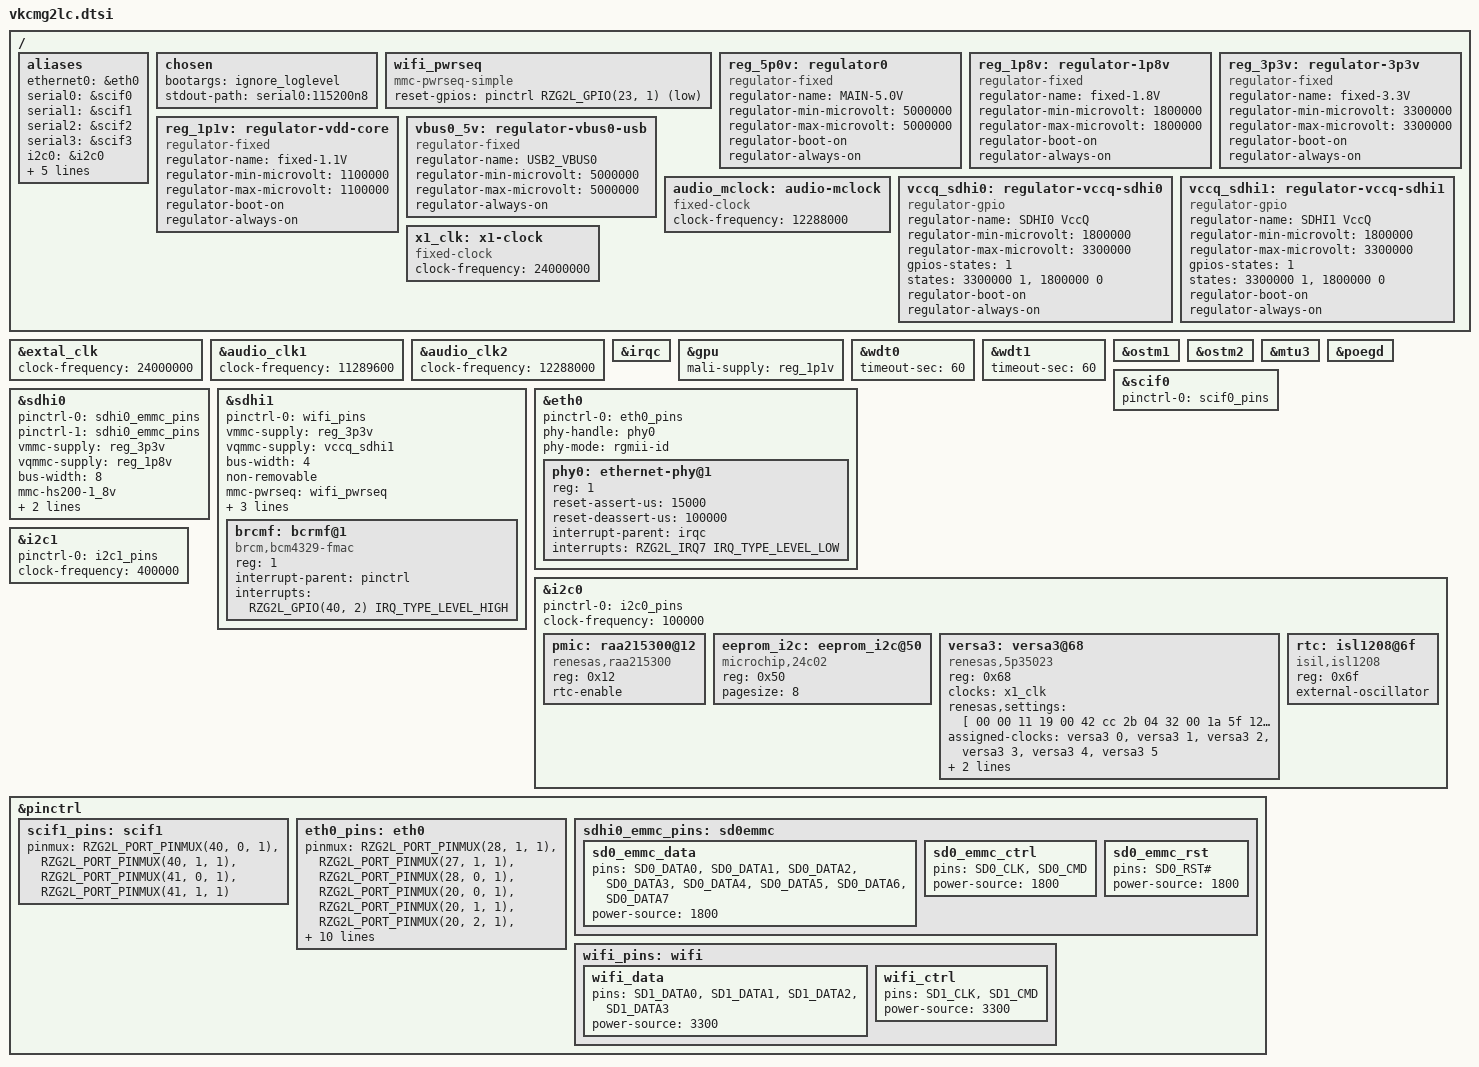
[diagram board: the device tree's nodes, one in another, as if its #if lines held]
// SPDX-License-Identifier: GPL-2.0
/*
 * Device Tree Source for the Vekatech (VKRZG2LC Dual Cortex-A55)
 *
 * Copyright (C) 2026 Vekatech.
 */

#include <dt-bindings/gpio/gpio.h>
#include <dt-bindings/interrupt-controller/irqc-rzg2l.h>
#include <dt-bindings/pinctrl/rzg2l-pinctrl.h>
#include <dt-bindings/input/input.h>


/ {
	aliases {
		ethernet0 = &eth0;
		serial0 = &scif0;
		serial1 = &scif1;
		serial2 = &scif2;
		serial3 = &scif3;
		i2c0 = &i2c0;
		i2c1 = &i2c1;
		i2c2 = &i2c2;
		i2c3 = &i2c3;
		mmc0 = &sdhi0;
		mmc1 = &sdhi1;
	};

	chosen {
		bootargs = "ignore_loglevel";
		stdout-path = "serial0:115200n8";
	};

#if WIFI_MODULE_1YN
	wifi_pwrseq: wifi_pwrseq {
		compatible = "mmc-pwrseq-simple";
		reset-gpios = <&pinctrl RZG2L_GPIO(23, 1) GPIO_ACTIVE_LOW>;
	};
#endif
	reg_5p0v: regulator0 {
		compatible = "regulator-fixed";
		regulator-name = "MAIN-5.0V";
		regulator-min-microvolt = <5000000>;
		regulator-max-microvolt = <5000000>;
		regulator-boot-on;
		regulator-always-on;
	};

	reg_1p8v: regulator-1p8v {
		compatible = "regulator-fixed";
		regulator-name = "fixed-1.8V";
		regulator-min-microvolt = <1800000>;
		regulator-max-microvolt = <1800000>;
		regulator-boot-on;
		regulator-always-on;
	};

	reg_3p3v: regulator-3p3v {
		compatible = "regulator-fixed";
		regulator-name = "fixed-3.3V";
		regulator-min-microvolt = <3300000>;
		regulator-max-microvolt = <3300000>;
		regulator-boot-on;
		regulator-always-on;
	};

	reg_1p1v: regulator-vdd-core {
		compatible = "regulator-fixed";
		regulator-name = "fixed-1.1V";
		regulator-min-microvolt = <1100000>;
		regulator-max-microvolt = <1100000>;
		regulator-boot-on;
		regulator-always-on;
	};

	vbus0_5v: regulator-vbus0-usb {
		compatible = "regulator-fixed";
		regulator-name = "USB2_VBUS0";
		regulator-min-microvolt = <5000000>;
		regulator-max-microvolt = <5000000>;
		regulator-always-on;
	};

	audio_mclock: audio-mclock {
		compatible = "fixed-clock";
		#clock-cells = <0>;
		clock-frequency = <12288000>;
	};

	vccq_sdhi0: regulator-vccq-sdhi0 {
		compatible = "regulator-gpio";
		regulator-name = "SDHI0 VccQ";
		regulator-min-microvolt = <1800000>;
		regulator-max-microvolt = <3300000>;
		gpios-states = <1>;
		states = <3300000 1>, <1800000 0>;
		regulator-boot-on;
		regulator-always-on;
	};

	vccq_sdhi1: regulator-vccq-sdhi1 {
		compatible = "regulator-gpio";
		regulator-name = "SDHI1 VccQ";
		regulator-min-microvolt = <1800000>;
		regulator-max-microvolt = <3300000>;
		gpios-states = <1>;
		states = <3300000 1>, <1800000 0>;
		regulator-boot-on;
		regulator-always-on;
	};

	x1_clk: x1-clock {
		compatible = "fixed-clock";
		#clock-cells = <0>;
		clock-frequency = <24000000>;
	};
};

&extal_clk {
	clock-frequency = <24000000>;
};

&audio_clk1{
	clock-frequency = <11289600>;
};

&audio_clk2{
	clock-frequency = <12288000>;
};

&irqc {
	status = "okay";
};

&gpu {
	mali-supply = <&reg_1p1v>;
};

&wdt0 {
	status = "okay";
	timeout-sec = <60>;
};

&wdt1 {
	status = "okay";
	timeout-sec = <60>;
};

&ostm1 {
	status = "okay";
};

&ostm2 {
	status = "okay";
};

&mtu3 {
	status = "okay";
};

&poegd {
	status = "okay";
};

&scif0 {
	pinctrl-0 = <&scif0_pins>;
	pinctrl-names = "default";
	status = "okay";
};

/* for eMMC */
&sdhi0 {
	pinctrl-0 = <&sdhi0_emmc_pins>;
	pinctrl-1 = <&sdhi0_emmc_pins>;
	pinctrl-names = "default", "state_uhs";

	vmmc-supply = <&reg_3p3v>;
	vqmmc-supply = <&reg_1p8v>;
	bus-width = <8>;
	mmc-hs200-1_8v;
	non-removable;
	fixed-emmc-driver-type = <1>;
	status = "okay";
};

#if WIFI_MODULE_1YN

/* Wifi */
&sdhi1 {
	status = "okay";

	#address-cells = <1>;
	#size-cells = <0>;

	pinctrl-names = "default";
	pinctrl-0 = <&wifi_pins>;
	vmmc-supply = <&reg_3p3v>;
	vqmmc-supply = <&vccq_sdhi1>;
	bus-width = <4>;
	non-removable;
	mmc-pwrseq = <&wifi_pwrseq>;
        cap-sd-highspeed;
	cap-power-off-card;
	keep-power-in-suspend;

	brcmf: bcrmf@1 {
		reg = <1>;
		compatible = "brcm,bcm4329-fmac";
		status = "okay";
		interrupt-parent = <&pinctrl>;
		interrupts = <RZG2L_GPIO(40, 2) IRQ_TYPE_LEVEL_HIGH>;
		interrupt-names = "host-wake";
	};
};
#endif

&eth0 {
	#address-cells = <1>;
	#size-cells = <0>;
	pinctrl-names = "default";
	pinctrl-0 = <&eth0_pins>;
	phy-handle = <&phy0>;
	phy-mode = "rgmii-id";
	status = "okay";

	/* Realtek RTL8211F (0x001cc916) */
	phy0: ethernet-phy@1 {
		reg = <1>;
		reset-assert-us = <15000>;
		reset-deassert-us = <100000>;
		interrupt-parent = <&irqc>;
		interrupts = <RZG2L_IRQ7 IRQ_TYPE_LEVEL_LOW>;
	};
};

&i2c0 {
	pinctrl-0 = <&i2c0_pins>;
	pinctrl-names = "default";

	clock-frequency = <100000>;
	status = "okay";

	pmic: raa215300@12 {
		compatible = "renesas,raa215300";
		reg = <0x12>;

		rtc-enable;
	};

	eeprom_i2c: eeprom_i2c@50 {
		status = "okay";
		compatible = "microchip,24c02", "atmel,24c02";
		reg = <0x50>;
		pagesize = <8>;
	};

	versa3: versa3@68 {
		compatible = "renesas,5p35023";
		reg = <0x68>;
		#clock-cells = <1>;
		clocks = <&x1_clk>;
		clock-names = "x1";

		renesas,settings = [
		    00 00 11 19 00 42 cc 2b 04 32 00 1a 5f 12 90 79
		    02 4c 00 00 00 00 00 00 10 24 19 bf 3f 30 90 86
		    80 42 45 c4 9c
		];

		assigned-clocks = <&versa3 0>,	/* REF RZ EXT */
				  <&versa3 1>,	/* SE1 Audio CLK1 */
				  <&versa3 2>,	/* SE2 Audio Master CLK */
				  <&versa3 3>,	/* SE3 32768Hz CLK */
				  <&versa3 4>,	/* DIFF1 ETH1/2 CLK */
				  <&versa3 5>;	/* DIFF2 Audio CLK2 */

		assigned-clock-rates =	<24000000>, 
					<11289600>,
		                        <12288000>, 
					<32768>,
		                        <25000000>, 
					<12288000>;
	};

	rtc: isl1208@6f {
		compatible = "isil,isl1208";
		reg = <0x6f>;

		external-oscillator;
	};
};

&i2c1 {
	status = "okay";

	pinctrl-0 = <&i2c1_pins>;
	pinctrl-names = "default";
	clock-frequency = <400000>;

};


&pinctrl {

#if WIFI_MODULE_1YN
	scif1_pins: scif1 {
		pinmux = <RZG2L_PORT_PINMUX(40, 0, 1)>, /* TxD */
			 <RZG2L_PORT_PINMUX(40, 1, 1)>, /* RxD */
			 <RZG2L_PORT_PINMUX(41, 0, 1)>, /* CTS# */
			 <RZG2L_PORT_PINMUX(41, 1, 1)>; /* RTS# */
	};
#endif

	eth0_pins: eth0 {
		pinmux = <RZG2L_PORT_PINMUX(28, 1, 1)>, /* ET0_LINKSTA */
			 <RZG2L_PORT_PINMUX(27, 1, 1)>, /* ET0_MDC */
			 <RZG2L_PORT_PINMUX(28, 0, 1)>, /* ET0_MDIO */
			 <RZG2L_PORT_PINMUX(20, 0, 1)>, /* ET0_TXC */
			 <RZG2L_PORT_PINMUX(20, 1, 1)>, /* ET0_TX_CTL */
			 <RZG2L_PORT_PINMUX(20, 2, 1)>, /* ET0_TXD0 */
			 <RZG2L_PORT_PINMUX(21, 0, 1)>, /* ET0_TXD1 */
			 <RZG2L_PORT_PINMUX(21, 1, 1)>, /* ET0_TXD2 */
			 <RZG2L_PORT_PINMUX(22, 0, 1)>, /* ET0_TXD3 */
			 <RZG2L_PORT_PINMUX(24, 0, 1)>, /* ET0_RXC */
			 <RZG2L_PORT_PINMUX(24, 1, 1)>, /* ET0_RX_CTL */
			 <RZG2L_PORT_PINMUX(25, 0, 1)>, /* ET0_RXD0 */
			 <RZG2L_PORT_PINMUX(25, 1, 1)>, /* ET0_RXD1 */
			 <RZG2L_PORT_PINMUX(26, 0, 1)>, /* ET0_RXD2 */
			 <RZG2L_PORT_PINMUX(26, 1, 1)>, /* ET0_RXD3 */
			 <RZG2L_PORT_PINMUX(43, 3, 4)>; /* IRQ7     */
	};

	sdhi0_emmc_pins: sd0emmc {
		sd0_emmc_data {
			pins = "SD0_DATA0", "SD0_DATA1", "SD0_DATA2", "SD0_DATA3",
			       "SD0_DATA4", "SD0_DATA5", "SD0_DATA6", "SD0_DATA7";
			power-source = <1800>;
		};

		sd0_emmc_ctrl {
			pins = "SD0_CLK", "SD0_CMD";
			power-source = <1800>;
		};

		sd0_emmc_rst {
			pins = "SD0_RST#";
			power-source = <1800>;
		};
	};
#if WIFI_MODULE_1YN
	wifi_pins: wifi {
		wifi_data {
			pins = "SD1_DATA0", "SD1_DATA1", "SD1_DATA2", "SD1_DATA3";
			power-source  = <3300>;
		};

		wifi_ctrl {
			pins = "SD1_CLK", "SD1_CMD";
			power-source  = <3300>;
		};
	};
#endif
};
